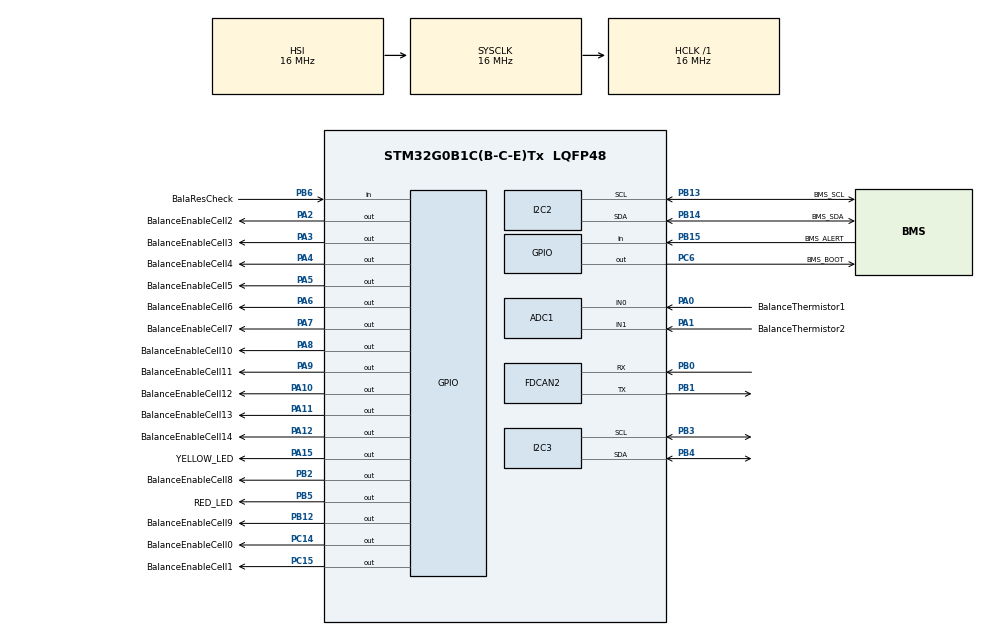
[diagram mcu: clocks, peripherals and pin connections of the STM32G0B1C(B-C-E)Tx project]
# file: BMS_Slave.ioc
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ADC1.Channel-0\#ChannelRegularConversion=ADC_CHANNEL_0
ADC1.NbrOfConversionFlag=1
ADC1.Rank-0\#ChannelRegularConversion=1
ADC1.SamplingTime-0\#ChannelRegularConversion=ADC_SAMPLINGTIME_COMMON_1
ADC1.SelectedChannel=ADC_CHANNEL_0|ADC_CHANNEL_1
ADC1.master=1
FDCAN2.CalculateBaudRateNominal=250000
FDCAN2.CalculateTimeBitNominal=4000
FDCAN2.CalculateTimeQuantumNominal=1000.0
FDCAN2.NominalTimeSeg1=2
FDCAN2.TransmitPause=ENABLE
FREERTOS.BinarySemaphores01=reg_pull,Dynamic,NULL,Available;can_push,Dynamic,NULL,Depleted
FREERTOS.Tasks01=defaultTask,24,128,StartDefaultTask,Default,NULL,Dynamic,NULL,NULL;BatteryManager,40,128,Cell_Motoring_Task,As external,NULL,Dynamic,NULL,NULL;CAN_Send,24,128,can_send_Task,As external,NULL,Dynamic,NULL,NULL
FREERTOS.configUSE_NEWLIB_REENTRANT=1
I2C2.Timing=0x00503D58
I2C3.Timing=0x00503D58
Mcu.Family=STM32G0
Mcu.Name=STM32G0B1C(B-C-E)Tx
Mcu.Package=LQFP48
PA0.GPIO_Label=BalanceThermistor1
PA0.Signal=SharedAnalog_PA0
PA1.GPIO_Label=BalanceThermistor2
PA1.Mode=IN1
PA1.Signal=ADC1_IN1
PA10.GPIO_Label=BalanceEnableCell12
PA10.Signal=GPIO_Output
PA11\ [PA9].GPIO_Label=BalanceEnableCell13
PA11\ [PA9].GPIO_PuPd=GPIO_PULLUP
PA11\ [PA9].Signal=GPIO_Output
PA12\ [PA10].GPIO_Label=BalanceEnableCell14
PA12\ [PA10].Signal=GPIO_Output
PA13.Mode=Serial_Wire
PA13.Signal=SYS_SWDIO
PA14-BOOT0.Mode=Serial_Wire
PA14-BOOT0.Signal=SYS_SWCLK
PA15.GPIO_Label=YELLOW_LED
PA15.GPIO_PuPd=GPIO_PULLUP
PA15.Signal=GPIO_Output
PA2.GPIO_Label=BalanceEnableCell2
PA2.GPIO_PuPd=GPIO_PULLUP
PA2.Signal=GPIO_Output
PA3.GPIO_Label=BalanceEnableCell3
PA3.GPIO_ModeDefaultOutputPP=GPIO_MODE_OUTPUT_PP
PA3.GPIO_PuPd=GPIO_PULLUP
PA3.Signal=GPIO_Output
PA4.GPIO_Label=BalanceEnableCell4
PA4.GPIO_PuPd=GPIO_PULLUP
PA4.Signal=GPIO_Output
PA5.GPIO_Label=BalanceEnableCell5
PA5.GPIO_PuPd=GPIO_PULLUP
PA5.Signal=GPIO_Output
PA6.GPIO_Label=BalanceEnableCell6
PA6.GPIO_PuPd=GPIO_PULLUP
PA6.Signal=GPIO_Output
PA7.GPIO_Label=BalanceEnableCell7
PA7.GPIO_PuPd=GPIO_PULLUP
PA7.Signal=GPIO_Output
PA8.GPIO_Label=BalanceEnableCell10
PA8.GPIO_PuPd=GPIO_PULLUP
PA8.Signal=GPIO_Output
PA9.GPIO_Label=BalanceEnableCell11
PA9.GPIO_PuPd=GPIO_PULLUP
PA9.Signal=GPIO_Output
PB0.GPIO_PuPd=GPIO_PULLUP
PB0.Mode=FDCAN_Activate
PB0.Signal=FDCAN2_RX
PB1.GPIO_PuPd=GPIO_PULLUP
PB1.Mode=FDCAN_Activate
PB1.Signal=FDCAN2_TX
PB10.Signal=USART3_TX
PB11.Signal=USART3_RX
PB12.GPIO_Label=BalanceEnableCell9
PB12.Signal=GPIO_Output
PB13.GPIO_Label=BMS_SCL
PB13.GPIO_Mode=GPIO_MODE_AF_OD
PB13.GPIO_Pu=GPIO_PULLUP
PB13.GPIO_Speed=GPIO_SPEED_FREQ_MEDIUM
PB13.Mode=I2C
PB13.Signal=I2C2_SCL
PB14.GPIO_Label=BMS_SDA
PB14.GPIO_Pu=GPIO_PULLUP
PB14.GPIO_Speed=GPIO_SPEED_FREQ_MEDIUM
PB14.Mode=I2C
PB14.Signal=I2C2_SDA
PB15.GPIO_Label=BMS_ALERT
PB15.GPIO_PuPd=GPIO_PULLDOWN
PB15.Signal=GPIO_Input
PB2.GPIO_Label=BalanceEnableCell8
PB2.GPIO_PuPd=GPIO_PULLUP
PB2.Signal=GPIO_Output
PB3.Mode=I2C
PB3.Signal=I2C3_SCL
PB4.Mode=I2C
PB4.Signal=I2C3_SDA
PB5.GPIO_Label=RED_LED
PB5.GPIO_PuPd=GPIO_PULLUP
PB5.Signal=GPIO_Output
PB6.GPIO_Label=BalaResCheck
PB6.Signal=GPIO_Input
PC14-OSC32_IN\ (PC14).GPIO_Label=BalanceEnableCell0
PC14-OSC32_IN\ (PC14).GPIO_PuPd=GPIO_PULLUP
PC14-OSC32_IN\ (PC14).Signal=GPIO_Output
PC15-OSC32_OUT\ (PC15).GPIO_Label=BalanceEnableCell1
PC15-OSC32_OUT\ (PC15).GPIO_PuPd=GPIO_PULLUP
PC15-OSC32_OUT\ (PC15).Signal=GPIO_Output
PC6.GPIO_Label=BMS_BOOT
PC6.Signal=GPIO_Output
PF0-OSC_IN\ (PF0).Mode=HSE-External-Clock-Source
PF0-OSC_IN\ (PF0).Signal=RCC_OSC_IN
PF1-OSC_OUT\ (PF1).Mode=OSC enable
PF1-OSC_OUT\ (PF1).Signal=RCC_OSC_EN
ProjectManager.HeapSize=0x200
ProjectManager.StackSize=0x400
ProjectManager.TargetToolchain=STM32CubeIDE
RCC.AHBFreq_Value=16000000
RCC.CortexFreq_Value=16000000
RCC.EXTERNAL_CLOCK_VALUE=48000
RCC.HCLKFreq_Value=16000000
RCC.HSE_VALUE=8000000
RCC.HSI48_VALUE=48000000
RCC.HSI_VALUE=16000000
RCC.LSE_VALUE=32768
RCC.SYSCLKFreq_VALUE=16000000
RCC.USBFreq_Value=48000000
RCC.VCOOutputFreq_Value=128000000
SH.SharedAnalog_PA0.0=GPIO_Analog
SH.SharedAnalog_PA0.1=ADC1_IN0,IN0
VP_FREERTOS_VS_CMSIS_V2.Mode=CMSIS_V2
VP_SYS_VS_DBSignals.Mode=DisableDeadBatterySignals
board=custom

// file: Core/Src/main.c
/* USER CODE BEGIN Header */
/**
  ******************************************************************************
  * @file           : main.c
  * @brief          : Main program body
  ******************************************************************************
  * @attention
  *
  * Copyright (c) 2025 STMicroelectronics.
  * All rights reserved.
  *
  * This software is licensed under terms that can be found in the LICENSE file
  * in the root directory of this software component.
  * If no LICENSE file comes with this software, it is provided AS-IS.
  *
  ******************************************************************************
  */
/* USER CODE END Header */
#include "main.h"
#include "cmsis_os.h"

/* USER CODE BEGIN Includes */
#include "cell_monitoring.h"

/* USER CODE END Includes */

ADC_HandleTypeDef hadc1;

FDCAN_HandleTypeDef hfdcan2;

I2C_HandleTypeDef hi2c2;
I2C_HandleTypeDef hi2c3;

/* Definitions for defaultTask */
osThreadId_t defaultTaskHandle;
const osThreadAttr_t defaultTask_attributes = {
  .name = "defaultTask",
  .priority = (osPriority_t) osPriorityNormal,
  .stack_size = 128 * 4
};
/* Definitions for BatteryManager */
osThreadId_t BatteryManagerHandle;
const osThreadAttr_t BatteryManager_attributes = {
  .name = "BatteryManager",
  .priority = (osPriority_t) osPriorityHigh,
  .stack_size = 128 * 4
};
/* Definitions for CAN_Send */
osThreadId_t CAN_SendHandle;
const osThreadAttr_t CAN_Send_attributes = {
  .name = "CAN_Send",
  .priority = (osPriority_t) osPriorityNormal,
  .stack_size = 128 * 4
};
/* Definitions for reg_pull */
osSemaphoreId_t reg_pullHandle;
const osSemaphoreAttr_t reg_pull_attributes = {
  .name = "reg_pull"
};
/* Definitions for can_push */
osSemaphoreId_t can_pushHandle;
const osSemaphoreAttr_t can_push_attributes = {
  .name = "can_push"
};

void SystemClock_Config(void);
static void MX_GPIO_Init(void);
static void MX_ADC1_Init(void);
static void MX_I2C3_Init(void);
static void MX_I2C2_Init(void);
static void MX_FDCAN2_Init(void);
void StartDefaultTask(void *argument);
extern void Cell_Motoring_Task(void *argument);
extern void can_send_Task(void *argument);

int main(void)
{

  /* MCU Configuration--------------------------------------------------------*/

  /* Reset of all peripherals, Initializes the Flash interface and the Systick. */
  HAL_Init();

  /* Configure the system clock */
  SystemClock_Config();

  /* Initialize all configured peripherals */
  MX_GPIO_Init();
  MX_ADC1_Init();
  MX_I2C3_Init();
  MX_I2C2_Init();
  MX_FDCAN2_Init();

  /* Init scheduler */
  osKernelInitialize();

  /* Create the semaphores(s) */
  /* creation of reg_pull */
  reg_pullHandle = osSemaphoreNew(1, 1, &reg_pull_attributes);

  /* creation of can_push */
  can_pushHandle = osSemaphoreNew(1, 0, &can_push_attributes);

  /* Create the thread(s) */
  /* creation of defaultTask */
  defaultTaskHandle = osThreadNew(StartDefaultTask, NULL, &defaultTask_attributes);

  /* creation of BatteryManager */
  BatteryManagerHandle = osThreadNew(Cell_Motoring_Task, NULL, &BatteryManager_attributes);

  /* creation of CAN_Send */
  CAN_SendHandle = osThreadNew(can_send_Task, NULL, &CAN_Send_attributes);

  /* Start scheduler */
  osKernelStart();

  /* We should never get here as control is now taken by the scheduler */

  /* Infinite loop */
  /* USER CODE BEGIN WHILE */
  while (1)
  {
	//Cell_Motoring_Task();
    /* USER CODE END WHILE */

  }
}

void SystemClock_Config(void)
{
  RCC_OscInitTypeDef RCC_OscInitStruct = {0};
  RCC_ClkInitTypeDef RCC_ClkInitStruct = {0};

  /** Configure the main internal regulator output voltage
  */
  HAL_PWREx_ControlVoltageScaling(PWR_REGULATOR_VOLTAGE_SCALE1);

  /** Initializes the RCC Oscillators according to the specified parameters
  * in the RCC_OscInitTypeDef structure.
  */
  RCC_OscInitStruct.OscillatorType = RCC_OSCILLATORTYPE_HSI;
  RCC_OscInitStruct.HSIState = RCC_HSI_ON;
  RCC_OscInitStruct.HSIDiv = RCC_HSI_DIV1;
  RCC_OscInitStruct.HSICalibrationValue = RCC_HSICALIBRATION_DEFAULT;
  RCC_OscInitStruct.PLL.PLLState = RCC_PLL_NONE;
  if (HAL_RCC_OscConfig(&RCC_OscInitStruct) != HAL_OK)
  {
    Error_Handler();
  }

  /** Initializes the CPU, AHB and APB buses clocks
  */
  RCC_ClkInitStruct.ClockType = RCC_CLOCKTYPE_HCLK|RCC_CLOCKTYPE_SYSCLK
                              |RCC_CLOCKTYPE_PCLK1;
  RCC_ClkInitStruct.SYSCLKSource = RCC_SYSCLKSOURCE_HSI;
  RCC_ClkInitStruct.AHBCLKDivider = RCC_SYSCLK_DIV1;
  RCC_ClkInitStruct.APB1CLKDivider = RCC_HCLK_DIV1;

  if (HAL_RCC_ClockConfig(&RCC_ClkInitStruct, FLASH_LATENCY_0) != HAL_OK)
  {
    Error_Handler();
  }
}

static void MX_ADC1_Init(void)
{

  ADC_ChannelConfTypeDef sConfig = {0};

  /** Configure the global features of the ADC (Clock, Resolution, Data Alignment and number of conversion)
  */
  hadc1.Instance = ADC1;
  hadc1.Init.ClockPrescaler = ADC_CLOCK_SYNC_PCLK_DIV2;
  hadc1.Init.Resolution = ADC_RESOLUTION_12B;
  hadc1.Init.DataAlign = ADC_DATAALIGN_RIGHT;
  hadc1.Init.ScanConvMode = ADC_SCAN_DISABLE;
  hadc1.Init.EOCSelection = ADC_EOC_SINGLE_CONV;
  hadc1.Init.LowPowerAutoWait = DISABLE;
  hadc1.Init.LowPowerAutoPowerOff = DISABLE;
  hadc1.Init.ContinuousConvMode = DISABLE;
  hadc1.Init.NbrOfConversion = 1;
  hadc1.Init.DiscontinuousConvMode = DISABLE;
  hadc1.Init.ExternalTrigConv = ADC_SOFTWARE_START;
  hadc1.Init.ExternalTrigConvEdge = ADC_EXTERNALTRIGCONVEDGE_NONE;
  hadc1.Init.DMAContinuousRequests = DISABLE;
  hadc1.Init.Overrun = ADC_OVR_DATA_PRESERVED;
  hadc1.Init.SamplingTimeCommon1 = ADC_SAMPLETIME_1CYCLE_5;
  hadc1.Init.SamplingTimeCommon2 = ADC_SAMPLETIME_1CYCLE_5;
  hadc1.Init.OversamplingMode = DISABLE;
  hadc1.Init.TriggerFrequencyMode = ADC_TRIGGER_FREQ_HIGH;
  if (HAL_ADC_Init(&hadc1) != HAL_OK)
  {
    Error_Handler();
  }

  /** Configure Regular Channel
  */
  sConfig.Channel = ADC_CHANNEL_0;
  sConfig.Rank = ADC_REGULAR_RANK_1;
  sConfig.SamplingTime = ADC_SAMPLINGTIME_COMMON_1;
  if (HAL_ADC_ConfigChannel(&hadc1, &sConfig) != HAL_OK)
  {
    Error_Handler();
  }

}

static void MX_FDCAN2_Init(void)
{

  hfdcan2.Instance = FDCAN2;
  hfdcan2.Init.ClockDivider = FDCAN_CLOCK_DIV1;
  hfdcan2.Init.FrameFormat = FDCAN_FRAME_CLASSIC;
  hfdcan2.Init.Mode = FDCAN_MODE_NORMAL;
  hfdcan2.Init.AutoRetransmission = DISABLE;
  hfdcan2.Init.TransmitPause = ENABLE;
  hfdcan2.Init.ProtocolException = DISABLE;
  hfdcan2.Init.NominalPrescaler = 16;
  hfdcan2.Init.NominalSyncJumpWidth = 1;
  hfdcan2.Init.NominalTimeSeg1 = 2;
  hfdcan2.Init.NominalTimeSeg2 = 1;
  hfdcan2.Init.DataPrescaler = 1;
  hfdcan2.Init.DataSyncJumpWidth = 1;
  hfdcan2.Init.DataTimeSeg1 = 1;
  hfdcan2.Init.DataTimeSeg2 = 1;
  hfdcan2.Init.StdFiltersNbr = 0;
  hfdcan2.Init.ExtFiltersNbr = 0;
  hfdcan2.Init.TxFifoQueueMode = FDCAN_TX_FIFO_OPERATION;
  if (HAL_FDCAN_Init(&hfdcan2) != HAL_OK)
  {
    Error_Handler();
  }

}

static void MX_I2C2_Init(void)
{

  hi2c2.Instance = I2C2;
  hi2c2.Init.Timing = 0x00503D58;
  hi2c2.Init.OwnAddress1 = 0;
  hi2c2.Init.AddressingMode = I2C_ADDRESSINGMODE_7BIT;
  hi2c2.Init.DualAddressMode = I2C_DUALADDRESS_DISABLE;
  hi2c2.Init.OwnAddress2 = 0;
  hi2c2.Init.OwnAddress2Masks = I2C_OA2_NOMASK;
  hi2c2.Init.GeneralCallMode = I2C_GENERALCALL_DISABLE;
  hi2c2.Init.NoStretchMode = I2C_NOSTRETCH_DISABLE;
  if (HAL_I2C_Init(&hi2c2) != HAL_OK)
  {
    Error_Handler();
  }

  /** Configure Analogue filter
  */
  if (HAL_I2CEx_ConfigAnalogFilter(&hi2c2, I2C_ANALOGFILTER_ENABLE) != HAL_OK)
  {
    Error_Handler();
  }

  /** Configure Digital filter
  */
  if (HAL_I2CEx_ConfigDigitalFilter(&hi2c2, 0) != HAL_OK)
  {
    Error_Handler();
  }

}

static void MX_I2C3_Init(void)
{

  hi2c3.Instance = I2C3;
  hi2c3.Init.Timing = 0x00503D58;
  hi2c3.Init.OwnAddress1 = 0;
  hi2c3.Init.AddressingMode = I2C_ADDRESSINGMODE_7BIT;
  hi2c3.Init.DualAddressMode = I2C_DUALADDRESS_DISABLE;
  hi2c3.Init.OwnAddress2 = 0;
  hi2c3.Init.OwnAddress2Masks = I2C_OA2_NOMASK;
  hi2c3.Init.GeneralCallMode = I2C_GENERALCALL_DISABLE;
  hi2c3.Init.NoStretchMode = I2C_NOSTRETCH_DISABLE;
  if (HAL_I2C_Init(&hi2c3) != HAL_OK)
  {
    Error_Handler();
  }

  /** Configure Analogue filter
  */
  if (HAL_I2CEx_ConfigAnalogFilter(&hi2c3, I2C_ANALOGFILTER_ENABLE) != HAL_OK)
  {
    Error_Handler();
  }

  /** Configure Digital filter
  */
  if (HAL_I2CEx_ConfigDigitalFilter(&hi2c3, 0) != HAL_OK)
  {
    Error_Handler();
  }

}

static void MX_GPIO_Init(void)
{
  GPIO_InitTypeDef GPIO_InitStruct = {0};

  /* GPIO Ports Clock Enable */
  __HAL_RCC_GPIOC_CLK_ENABLE();
  __HAL_RCC_GPIOF_CLK_ENABLE();
  __HAL_RCC_GPIOA_CLK_ENABLE();
  __HAL_RCC_GPIOB_CLK_ENABLE();

  /*Configure GPIO pin Output Level */
  HAL_GPIO_WritePin(GPIOC, BalanceEnableCell0_Pin|BalanceEnableCell1_Pin|BMS_BOOT_Pin, GPIO_PIN_RESET);

  /*Configure GPIO pin Output Level */
  HAL_GPIO_WritePin(GPIOA, BalanceEnableCell2_Pin|BalanceEnableCell3_Pin|BalanceEnableCell4_Pin|BalanceEnableCell5_Pin
                          |BalanceEnableCell6_Pin|BalanceEnableCell7_Pin|BalanceEnableCell10_Pin|BalanceEnableCell11_Pin
                          |BalanceEnableCell12_Pin|BalanceEnableCell13_Pin|BalanceEnableCell14_Pin|YELLOW_LED_Pin, GPIO_PIN_RESET);

  /*Configure GPIO pin Output Level */
  HAL_GPIO_WritePin(GPIOB, BalanceEnableCell8_Pin|BalanceEnableCell9_Pin|RED_LED_Pin, GPIO_PIN_RESET);

  /*Configure GPIO pins : BalanceEnableCell0_Pin BalanceEnableCell1_Pin */
  GPIO_InitStruct.Pin = BalanceEnableCell0_Pin|BalanceEnableCell1_Pin;
  GPIO_InitStruct.Mode = GPIO_MODE_OUTPUT_PP;
  GPIO_InitStruct.Pull = GPIO_PULLUP;
  GPIO_InitStruct.Speed = GPIO_SPEED_FREQ_LOW;
  HAL_GPIO_Init(GPIOC, &GPIO_InitStruct);

  /*Configure GPIO pin : PF1 */
  GPIO_InitStruct.Pin = GPIO_PIN_1;
  GPIO_InitStruct.Mode = GPIO_MODE_AF_PP;
  GPIO_InitStruct.Pull = GPIO_NOPULL;
  GPIO_InitStruct.Speed = GPIO_SPEED_FREQ_LOW;
  GPIO_InitStruct.Alternate = GPIO_AF0_OSC;
  HAL_GPIO_Init(GPIOF, &GPIO_InitStruct);

  /*Configure GPIO pins : BalanceEnableCell2_Pin BalanceEnableCell3_Pin BalanceEnableCell4_Pin BalanceEnableCell5_Pin
                           BalanceEnableCell6_Pin BalanceEnableCell7_Pin BalanceEnableCell10_Pin BalanceEnableCell11_Pin
                           BalanceEnableCell13_Pin YELLOW_LED_Pin */
  GPIO_InitStruct.Pin = BalanceEnableCell2_Pin|BalanceEnableCell3_Pin|BalanceEnableCell4_Pin|BalanceEnableCell5_Pin
                          |BalanceEnableCell6_Pin|BalanceEnableCell7_Pin|BalanceEnableCell10_Pin|BalanceEnableCell11_Pin
                          |BalanceEnableCell13_Pin|YELLOW_LED_Pin;
  GPIO_InitStruct.Mode = GPIO_MODE_OUTPUT_PP;
  GPIO_InitStruct.Pull = GPIO_PULLUP;
  GPIO_InitStruct.Speed = GPIO_SPEED_FREQ_LOW;
  HAL_GPIO_Init(GPIOA, &GPIO_InitStruct);

  /*Configure GPIO pins : BalanceEnableCell8_Pin RED_LED_Pin */
  GPIO_InitStruct.Pin = BalanceEnableCell8_Pin|RED_LED_Pin;
  GPIO_InitStruct.Mode = GPIO_MODE_OUTPUT_PP;
  GPIO_InitStruct.Pull = GPIO_PULLUP;
  GPIO_InitStruct.Speed = GPIO_SPEED_FREQ_LOW;
  HAL_GPIO_Init(GPIOB, &GPIO_InitStruct);

  /*Configure GPIO pins : PB10 PB11 */
  GPIO_InitStruct.Pin = GPIO_PIN_10|GPIO_PIN_11;
  GPIO_InitStruct.Mode = GPIO_MODE_AF_PP;
  GPIO_InitStruct.Pull = GPIO_NOPULL;
  GPIO_InitStruct.Speed = GPIO_SPEED_FREQ_LOW;
  GPIO_InitStruct.Alternate = GPIO_AF4_USART3;
  HAL_GPIO_Init(GPIOB, &GPIO_InitStruct);

  /*Configure GPIO pin : BalanceEnableCell9_Pin */
  GPIO_InitStruct.Pin = BalanceEnableCell9_Pin;
  GPIO_InitStruct.Mode = GPIO_MODE_OUTPUT_PP;
  GPIO_InitStruct.Pull = GPIO_NOPULL;
  GPIO_InitStruct.Speed = GPIO_SPEED_FREQ_LOW;
  HAL_GPIO_Init(BalanceEnableCell9_GPIO_Port, &GPIO_InitStruct);

  /*Configure GPIO pin : BMS_ALERT_Pin */
  GPIO_InitStruct.Pin = BMS_ALERT_Pin;
  GPIO_InitStruct.Mode = GPIO_MODE_INPUT;
  GPIO_InitStruct.Pull = GPIO_PULLDOWN;
  HAL_GPIO_Init(BMS_ALERT_GPIO_Port, &GPIO_InitStruct);

  /*Configure GPIO pin : BMS_BOOT_Pin */
  GPIO_InitStruct.Pin = BMS_BOOT_Pin;
  GPIO_InitStruct.Mode = GPIO_MODE_OUTPUT_PP;
  GPIO_InitStruct.Pull = GPIO_NOPULL;
  GPIO_InitStruct.Speed = GPIO_SPEED_FREQ_LOW;
  HAL_GPIO_Init(BMS_BOOT_GPIO_Port, &GPIO_InitStruct);

  /*Configure GPIO pins : BalanceEnableCell12_Pin BalanceEnableCell14_Pin */
  GPIO_InitStruct.Pin = BalanceEnableCell12_Pin|BalanceEnableCell14_Pin;
  GPIO_InitStruct.Mode = GPIO_MODE_OUTPUT_PP;
  GPIO_InitStruct.Pull = GPIO_NOPULL;
  GPIO_InitStruct.Speed = GPIO_SPEED_FREQ_LOW;
  HAL_GPIO_Init(GPIOA, &GPIO_InitStruct);

  /*Configure GPIO pin : BalaResCheck_Pin */
  GPIO_InitStruct.Pin = BalaResCheck_Pin;
  GPIO_InitStruct.Mode = GPIO_MODE_INPUT;
  GPIO_InitStruct.Pull = GPIO_NOPULL;
  HAL_GPIO_Init(BalaResCheck_GPIO_Port, &GPIO_InitStruct);

}

void StartDefaultTask(void *argument)
{
  for(;;)
  {
    osDelay(1);
  }
}

void Error_Handler(void)
{
  __disable_irq();
  while (1)
  {
  }
}
